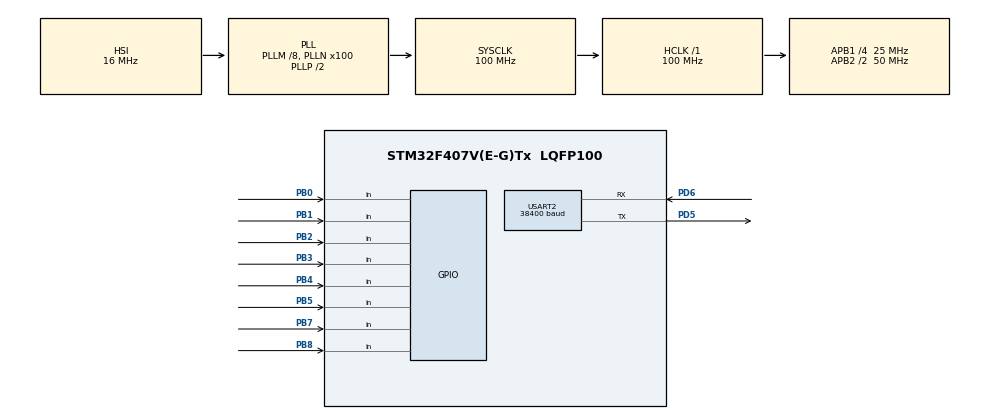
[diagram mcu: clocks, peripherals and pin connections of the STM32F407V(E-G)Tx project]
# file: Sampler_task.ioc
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Dma.Request0=USART2_TX
Dma.USART2_TX.0.Direction=DMA_MEMORY_TO_PERIPH
Dma.USART2_TX.0.FIFOMode=DMA_FIFOMODE_DISABLE
Dma.USART2_TX.0.Instance=DMA1_Stream6
Dma.USART2_TX.0.MemDataAlignment=DMA_MDATAALIGN_BYTE
Dma.USART2_TX.0.MemInc=DMA_MINC_ENABLE
Dma.USART2_TX.0.Mode=DMA_NORMAL
Dma.USART2_TX.0.PeriphDataAlignment=DMA_PDATAALIGN_BYTE
Dma.USART2_TX.0.PeriphInc=DMA_PINC_DISABLE
Dma.USART2_TX.0.Priority=DMA_PRIORITY_LOW
Mcu.Family=STM32F4
Mcu.Name=STM32F407V(E-G)Tx
Mcu.Package=LQFP100
NVIC.DMA1_Stream6_IRQn=true\:0\:0\:false\:false\:true\:true\:true
NVIC.PriorityGroup=NVIC_PRIORITYGROUP_4
NVIC.TIM1_UP_TIM10_IRQn=true\:0\:0\:false\:false\:true\:false\:true
NVIC.TIM7_IRQn=true\:0\:0\:false\:false\:true\:true\:true
NVIC.TimeBase=TIM1_UP_TIM10_IRQn
NVIC.TimeBaseIP=TIM10
NVIC.USART2_IRQn=true\:0\:0\:false\:false\:true\:true\:true
PB0.GPIO_PuPd=GPIO_PULLDOWN
PB0.Signal=GPIO_Input
PB1.GPIO_PuPd=GPIO_PULLDOWN
PB1.Signal=GPIO_Input
PB2.GPIO_PuPd=GPIO_PULLDOWN
PB2.Signal=GPIO_Input
PB3.GPIO_PuPd=GPIO_PULLDOWN
PB3.Signal=GPIO_Input
PB4.GPIO_PuPd=GPIO_PULLDOWN
PB4.Signal=GPIO_Input
PB5.GPIO_PuPd=GPIO_PULLDOWN
PB5.Signal=GPIO_Input
PB7.GPIO_PuPd=GPIO_PULLDOWN
PB7.Signal=GPIO_Input
PB8.GPIO_PuPd=GPIO_PULLDOWN
PB8.Signal=GPIO_Input
PD5.Mode=Asynchronous
PD5.Signal=USART2_TX
PD6.Mode=Asynchronous
PD6.Signal=USART2_RX
ProjectManager.HeapSize=0x200
ProjectManager.StackSize=0x400
ProjectManager.TargetToolchain=STM32CubeIDE
RCC.48MHZClocksFreq_Value=50000000
RCC.AHBFreq_Value=100000000
RCC.APB1CLKDivider=RCC_HCLK_DIV4
RCC.APB1Freq_Value=25000000
RCC.APB1TimFreq_Value=50000000
RCC.APB2CLKDivider=RCC_HCLK_DIV2
RCC.APB2Freq_Value=50000000
RCC.APB2TimFreq_Value=100000000
RCC.CortexFreq_Value=100000000
RCC.HCLKFreq_Value=100000000
RCC.HSE_VALUE=25000000
RCC.HSI_VALUE=16000000
RCC.LSE_VALUE=32768
RCC.PLLM=8
RCC.PLLN=100
RCC.SYSCLKFreq_VALUE=100000000
RCC.SYSCLKSource=RCC_SYSCLKSOURCE_PLLCLK
RCC.VCOOutputFreq_Value=200000000
TIM7.AutoReloadPreload=TIM_AUTORELOAD_PRELOAD_ENABLE
TIM7.Period=100
TIM7.Prescaler=500
USART2.BaudRate=38400
USART2.VirtualMode=VM_ASYNC
VP_SYS_VS_tim10.Mode=TIM10
VP_TIM7_VS_ClockSourceINT.Mode=Enable_Timer
board=custom

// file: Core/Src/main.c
/* USER CODE BEGIN Header */
/**
  ******************************************************************************
  * @file           : main.c
  * @brief          : Main program body
  ******************************************************************************
  * @attention
  *
  * <h2><center>&copy; Copyright (c) 2020 STMicroelectronics.
  * All rights reserved.</center></h2>
  *
  * This software component is licensed by ST under BSD 3-Clause license,
  * the "License"; You may not use this file except in compliance with the
  * License. You may obtain a copy of the License at:
  *                        opensource.org/licenses/BSD-3-Clause
  *
  ******************************************************************************
  */
/* USER CODE END Header */

#include "main.h"

TIM_HandleTypeDef htim7;

UART_HandleTypeDef huart2;
DMA_HandleTypeDef hdma_usart2_tx;

/* USER CODE BEGIN PV */
volatile uint8_t pin_val;
volatile uint8_t byte_ready;
/* USER CODE END PV */

void SystemClock_Config(void);
static void MX_GPIO_Init(void);
static void MX_DMA_Init(void);
static void MX_USART2_UART_Init(void);
static void MX_TIM7_Init(void);

int main(void)
{

  /* MCU Configuration--------------------------------------------------------*/

  /* Reset of all peripherals, Initializes the Flash interface and the Systick. */
  HAL_Init();

  /* Configure the system clock */
  SystemClock_Config();

  /* Initialize all configured peripherals */
  MX_GPIO_Init();
  MX_DMA_Init();
  MX_USART2_UART_Init();
  MX_TIM7_Init();
  /* USER CODE BEGIN 2 */
  	sampler_init_pinout();
    sampler_init_ring_buf();
    sampler_precalc_crc16_lut();
    HAL_TIM_Base_Start_IT(&htim7);
  /* USER CODE END 2 */

  /* Infinite loop */
  /* USER CODE BEGIN WHILE */
    byte_ready = 0;
  while (1)
  {
	  if(byte_ready) {
		  byte_ready = 0;
		  sampler_create_packet();
	  }
    /* USER CODE END WHILE */

  }
}

void SystemClock_Config(void)
{
  RCC_OscInitTypeDef RCC_OscInitStruct = {0};
  RCC_ClkInitTypeDef RCC_ClkInitStruct = {0};

  /** Configure the main internal regulator output voltage
  */
  __HAL_RCC_PWR_CLK_ENABLE();
  __HAL_PWR_VOLTAGESCALING_CONFIG(PWR_REGULATOR_VOLTAGE_SCALE1);
  /** Initializes the CPU, AHB and APB busses clocks
  */
  RCC_OscInitStruct.OscillatorType = RCC_OSCILLATORTYPE_HSI;
  RCC_OscInitStruct.HSIState = RCC_HSI_ON;
  RCC_OscInitStruct.HSICalibrationValue = RCC_HSICALIBRATION_DEFAULT;
  RCC_OscInitStruct.PLL.PLLState = RCC_PLL_ON;
  RCC_OscInitStruct.PLL.PLLSource = RCC_PLLSOURCE_HSI;
  RCC_OscInitStruct.PLL.PLLM = 8;
  RCC_OscInitStruct.PLL.PLLN = 100;
  RCC_OscInitStruct.PLL.PLLP = RCC_PLLP_DIV2;
  RCC_OscInitStruct.PLL.PLLQ = 4;
  if (HAL_RCC_OscConfig(&RCC_OscInitStruct) != HAL_OK)
  {
    Error_Handler();
  }
  /** Initializes the CPU, AHB and APB busses clocks
  */
  RCC_ClkInitStruct.ClockType = RCC_CLOCKTYPE_HCLK|RCC_CLOCKTYPE_SYSCLK
                              |RCC_CLOCKTYPE_PCLK1|RCC_CLOCKTYPE_PCLK2;
  RCC_ClkInitStruct.SYSCLKSource = RCC_SYSCLKSOURCE_PLLCLK;
  RCC_ClkInitStruct.AHBCLKDivider = RCC_SYSCLK_DIV1;
  RCC_ClkInitStruct.APB1CLKDivider = RCC_HCLK_DIV4;
  RCC_ClkInitStruct.APB2CLKDivider = RCC_HCLK_DIV2;

  if (HAL_RCC_ClockConfig(&RCC_ClkInitStruct, FLASH_LATENCY_3) != HAL_OK)
  {
    Error_Handler();
  }
}

static void MX_TIM7_Init(void)
{

  TIM_MasterConfigTypeDef sMasterConfig = {0};

  htim7.Instance = TIM7;
  htim7.Init.Prescaler = 500;
  htim7.Init.CounterMode = TIM_COUNTERMODE_UP;
  htim7.Init.Period = 100;
  htim7.Init.AutoReloadPreload = TIM_AUTORELOAD_PRELOAD_ENABLE;
  if (HAL_TIM_Base_Init(&htim7) != HAL_OK)
  {
    Error_Handler();
  }
  sMasterConfig.MasterOutputTrigger = TIM_TRGO_RESET;
  sMasterConfig.MasterSlaveMode = TIM_MASTERSLAVEMODE_DISABLE;
  if (HAL_TIMEx_MasterConfigSynchronization(&htim7, &sMasterConfig) != HAL_OK)
  {
    Error_Handler();
  }

}

static void MX_USART2_UART_Init(void)
{

  huart2.Instance = USART2;
  huart2.Init.BaudRate = 38400;
  huart2.Init.WordLength = UART_WORDLENGTH_8B;
  huart2.Init.StopBits = UART_STOPBITS_1;
  huart2.Init.Parity = UART_PARITY_NONE;
  huart2.Init.Mode = UART_MODE_TX;
  huart2.Init.HwFlowCtl = UART_HWCONTROL_NONE;
  huart2.Init.OverSampling = UART_OVERSAMPLING_16;
  if (HAL_UART_Init(&huart2) != HAL_OK)
  {
    Error_Handler();
  }

}

static void MX_DMA_Init(void)
{

  /* DMA controller clock enable */
  __HAL_RCC_DMA1_CLK_ENABLE();

  /* DMA interrupt init */
  /* DMA1_Stream6_IRQn interrupt configuration */
  HAL_NVIC_SetPriority(DMA1_Stream6_IRQn, 0, 0);
  HAL_NVIC_EnableIRQ(DMA1_Stream6_IRQn);

}

static void MX_GPIO_Init(void)
{
  GPIO_InitTypeDef GPIO_InitStruct = {0};

  /* GPIO Ports Clock Enable */
  __HAL_RCC_GPIOB_CLK_ENABLE();
  __HAL_RCC_GPIOD_CLK_ENABLE();

  /*Configure GPIO pins : PB0 PB1 PB2 PB3
                           PB4 PB5 PB7 PB8 */
  GPIO_InitStruct.Pin = GPIO_PIN_0|GPIO_PIN_1|GPIO_PIN_2|GPIO_PIN_3
                          |GPIO_PIN_4|GPIO_PIN_5|GPIO_PIN_7|GPIO_PIN_8;
  GPIO_InitStruct.Mode = GPIO_MODE_INPUT;
  GPIO_InitStruct.Pull = GPIO_PULLDOWN;
  HAL_GPIO_Init(GPIOB, &GPIO_InitStruct);

}

 /**
  * @brief  Period elapsed callback in non blocking mode
  * @note   This function is called  when TIM10 interrupt took place, inside
  * HAL_TIM_IRQHandler(). It makes a direct call to HAL_IncTick() to increment
  * a global variable "uwTick" used as application time base.
  * @param  htim : TIM handle
  * @retval None
  */
void HAL_TIM_PeriodElapsedCallback(TIM_HandleTypeDef *htim)
{
  if (htim->Instance == TIM10) {
    HAL_IncTick();
  }
  /* USER CODE BEGIN Callback 1 */
  if (htim->Instance == TIM7) {
 	  pin_val = sampler_get_pin_val();
 	  sampler_push_byte(pin_val);
 	  byte_ready = 1;
   }
  /* USER CODE END Callback 1 */
}

void Error_Handler(void)
{
}

/************************ (C) COPYRIGHT STMicroelectronics *****END OF FILE****/
